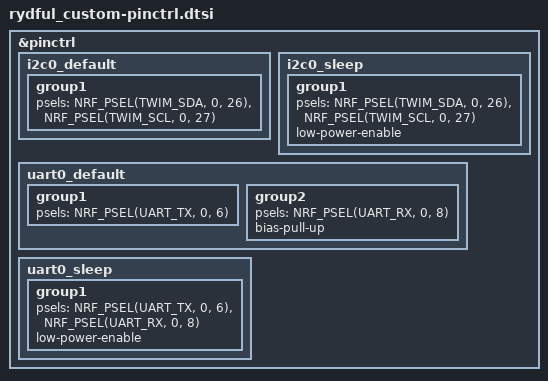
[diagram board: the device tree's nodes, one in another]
/*
 * SPDX-License-Identifier: Apache-2.0
 *
 * Pin control configuration for Rydful Custom PCB
 *
 * Adjust these pins to match your PCB layout!
 */

&pinctrl {
	/* I2C0 pins for LIS3DHTR */
	i2c0_default: i2c0_default {
		group1 {
			psels = <NRF_PSEL(TWIM_SDA, 0, 26)>,
			        <NRF_PSEL(TWIM_SCL, 0, 27)>;
		};
	};

	i2c0_sleep: i2c0_sleep {
		group1 {
			psels = <NRF_PSEL(TWIM_SDA, 0, 26)>,
			        <NRF_PSEL(TWIM_SCL, 0, 27)>;
			low-power-enable;
		};
	};

	/* UART0 pins (optional - for debug output) */
	uart0_default: uart0_default {
		group1 {
			psels = <NRF_PSEL(UART_TX, 0, 6)>;
		};
		group2 {
			psels = <NRF_PSEL(UART_RX, 0, 8)>;
			bias-pull-up;
		};
	};

	uart0_sleep: uart0_sleep {
		group1 {
			psels = <NRF_PSEL(UART_TX, 0, 6)>,
			        <NRF_PSEL(UART_RX, 0, 8)>;
			low-power-enable;
		};
	};
};
